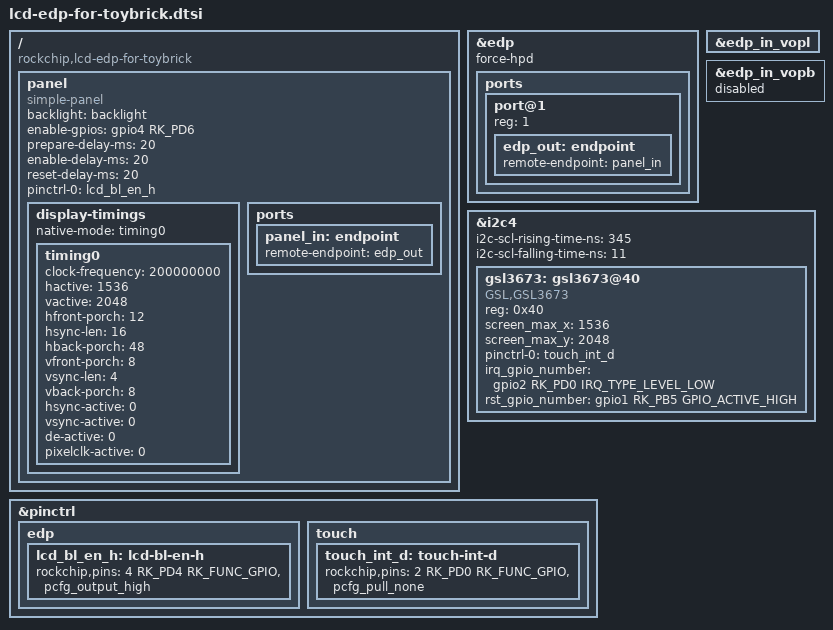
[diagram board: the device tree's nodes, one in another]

#include "rk3399pro.dtsi"

/ {
	compatible = "rockchip,lcd-edp-for-toybrick", "rockchip,rk3399pro";

	panel: panel {
		compatible = "simple-panel";
		backlight = <&backlight>;
		enable-gpios = <&gpio4 RK_PD6 GPIO_ACTIVE_HIGH>;
		prepare-delay-ms = <20>;
		enable-delay-ms = <20>;
		reset-delay-ms = <20>;

		pinctrl-names = "default";
		pinctrl-0 = <&lcd_bl_en_h>;
		display-timings {
			native-mode = <&timing0>;

			timing0: timing0 {
				clock-frequency = <200000000>;
				hactive = <1536>;
				vactive = <2048>;
				hfront-porch = <12>;
				hsync-len = <16>;
				hback-porch = <48>;
				vfront-porch = <8>;
				vsync-len = <4>;
				vback-porch = <8>;
				hsync-active = <0>;
				vsync-active = <0>;
				de-active = <0>;
				pixelclk-active = <0>;
			};
		};

		ports {
			panel_in: endpoint {
				remote-endpoint = <&edp_out>;
			};
		};
	};
};

&edp {
	status = "okay";
	force-hpd;

	ports {
		port@1 {
			reg = <1>;

			edp_out: endpoint {
				remote-endpoint = <&panel_in>;
			};
		};
	};
};

&edp_in_vopl {
	status = "okay";
};

&edp_in_vopb {
	status = "disabled";
};

&i2c4 {
	status = "okay";
	i2c-scl-rising-time-ns = <345>;
	i2c-scl-falling-time-ns = <11>;

	gsl3673: gsl3673@40 {
		compatible = "GSL,GSL3673";
		reg = <0x40>;
		screen_max_x = <1536>;
		screen_max_y = <2048>;

		pinctrl-names = "default";
		pinctrl-0 = <&touch_int_d>;
		irq_gpio_number = <&gpio2 RK_PD0 IRQ_TYPE_LEVEL_LOW>;
		rst_gpio_number = <&gpio1 RK_PB5 GPIO_ACTIVE_HIGH>;
	};
};

&pinctrl {
	edp {
		lcd_bl_en_h: lcd-bl-en-h {
			rockchip,pins =
				<4 RK_PD4 RK_FUNC_GPIO &pcfg_output_high>;
		};
	};
	touch {
		touch_int_d: touch-int-d {
			rockchip,pins =
				<2 RK_PD0 RK_FUNC_GPIO &pcfg_pull_none>;
		};
	};
};
